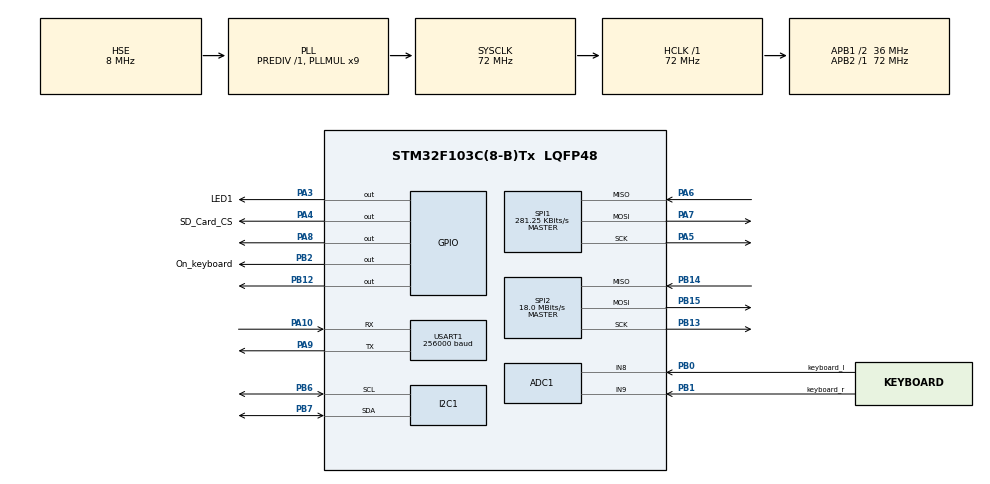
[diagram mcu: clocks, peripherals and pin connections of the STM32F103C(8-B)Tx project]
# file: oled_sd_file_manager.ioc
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ADC1.Channel-10\#ChannelRegularConversion=ADC_CHANNEL_8
ADC1.Channel-11\#ChannelRegularConversion=ADC_CHANNEL_9
ADC1.Channel-9\#ChannelRegularConversion=ADC_CHANNEL_8
ADC1.ContinuousConvMode=DISABLE
ADC1.DataAlign=ADC_DATAALIGN_RIGHT
ADC1.DiscontinuousConvMode=DISABLE
ADC1.EnableAnalogWatchDog=false
ADC1.EnableRegularConversion=ENABLE
ADC1.ExternalTrigConvEdgeChoice=NONE
ADC1.InjNumberOfConversion=0
ADC1.NbrOfConversion=2
ADC1.NbrOfConversionFlag=1
ADC1.Rank-10\#ChannelRegularConversion=2
ADC1.Rank-11\#ChannelRegularConversion=2
ADC1.Rank-9\#ChannelRegularConversion=1
ADC1.SamplingTime-10\#ChannelRegularConversion=ADC_SAMPLETIME_1CYCLE_5
ADC1.SamplingTime-11\#ChannelRegularConversion=ADC_SAMPLETIME_1CYCLE_5
ADC1.SamplingTime-9\#ChannelRegularConversion=ADC_SAMPLETIME_1CYCLE_5
ADC1.ScanConvMode=ADC_SCAN_ENABLE
ADC1.master=1
Dma.ADC1.0.Direction=DMA_PERIPH_TO_MEMORY
Dma.ADC1.0.Instance=DMA1_Channel1
Dma.ADC1.0.MemDataAlignment=DMA_MDATAALIGN_HALFWORD
Dma.ADC1.0.MemInc=DMA_MINC_ENABLE
Dma.ADC1.0.Mode=DMA_NORMAL
Dma.ADC1.0.PeriphDataAlignment=DMA_PDATAALIGN_HALFWORD
Dma.ADC1.0.PeriphInc=DMA_PINC_DISABLE
Dma.ADC1.0.Priority=DMA_PRIORITY_LOW
Dma.Request0=ADC1
I2C1.I2C_Mode=I2C_Fast
Mcu.Family=STM32F1
Mcu.Name=STM32F103C(8-B)Tx
Mcu.Package=LQFP48
NVIC.DMA1_Channel1_IRQn=true\:0\:0\:false
NVIC.PriorityGroup=NVIC_PRIORITYGROUP_4
NVIC.USART1_IRQn=true\:0\:0\:false
PA10.Mode=Asynchronous
PA10.Signal=USART1_RX
PA3.GPIO_Label=LED1
PA3.Signal=GPIO_Output
PA4.GPIO_Label=SD_Card_CS
PA4.Signal=GPIO_Output
PA5.Mode=Full_Duplex_Master
PA5.Signal=SPI1_SCK
PA6.Mode=Full_Duplex_Master
PA6.Signal=SPI1_MISO
PA7.Mode=Full_Duplex_Master
PA7.Signal=SPI1_MOSI
PA8.Signal=GPIO_Output
PA9.Mode=Asynchronous
PA9.Signal=USART1_TX
PB0.GPIO_Label=keyboard_l
PB0.Signal=ADCx_IN8
PB1.GPIO_Label=keyboard_r
PB1.Signal=ADCx_IN9
PB12.Signal=GPIO_Output
PB13.Mode=Full_Duplex_Master
PB13.Signal=SPI2_SCK
PB14.Mode=Full_Duplex_Master
PB14.Signal=SPI2_MISO
PB15.Mode=Full_Duplex_Master
PB15.Signal=SPI2_MOSI
PB2.GPIO_Label=On_keyboard
PB2.Signal=GPIO_Output
PB6.Mode=I2C
PB6.Signal=I2C1_SCL
PB7.Mode=I2C
PB7.Signal=I2C1_SDA
PD0-OSC_IN.Mode=HSE-External-Oscillator
PD0-OSC_IN.Signal=RCC_OSC_IN
PD1-OSC_OUT.Mode=HSE-External-Oscillator
PD1-OSC_OUT.Signal=RCC_OSC_OUT
ProjectManager.HeapSize=0x2710
ProjectManager.StackSize=0x200
ProjectManager.TargetToolchain=MDK-ARM V5
RCC.ADCPresc=RCC_ADCPCLK2_DIV6
RCC.AHBFreq_Value=72000000
RCC.APB1CLKDivider=RCC_HCLK_DIV2
RCC.APB1Freq_Value=36000000
RCC.APB1TimFreq_Value=72000000
RCC.APB2Freq_Value=72000000
RCC.APB2TimFreq_Value=72000000
RCC.HCLKFreq_Value=72000000
RCC.HSIState=RCC_HSI_ON
RCC.PLLMUL=RCC_PLL_MUL9
RCC.PLLSourceVirtual=RCC_PLLSOURCE_HSE
RCC.SYSCLKFreq_VALUE=72000000
RCC.SYSCLKSource=RCC_SYSCLKSOURCE_PLLCLK
RCC.USBFreq_Value=72000000
SH.ADCx_IN8.0=ADC1_IN8,IN8
SH.ADCx_IN9.0=ADC1_IN9,IN9
SPI1.BaudRatePrescaler=SPI_BAUDRATEPRESCALER_256
SPI1.CalculateBaudRate=281.25 KBits/s
SPI1.Mode=SPI_MODE_MASTER
SPI2.CalculateBaudRate=18.0 MBits/s
SPI2.Mode=SPI_MODE_MASTER
USART1.BaudRate=256000
board=oled_sd_file_manager

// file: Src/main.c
/**
  ******************************************************************************
  * File Name          : main.c
  * Description        : Main program body
  ******************************************************************************
  *
  * COPYRIGHT(c) 2016 STMicroelectronics
  *
  * Redistribution and use in source and binary forms, with or without modification,
  * are permitted provided that the following conditions are met:
  *   1. Redistributions of source code must retain the above copyright notice,
  *      this list of conditions and the following disclaimer.
  *   2. Redistributions in binary form must reproduce the above copyright notice,
  *      this list of conditions and the following disclaimer in the documentation
  *      and/or other materials provided with the distribution.
  *   3. Neither the name of STMicroelectronics nor the names of its contributors
  *      may be used to endorse or promote products derived from this software
  *      without specific prior written permission.
  *
  * THIS SOFTWARE IS PROVIDED BY THE COPYRIGHT HOLDERS AND CONTRIBUTORS "AS IS"
  * AND ANY EXPRESS OR IMPLIED WARRANTIES, INCLUDING, BUT NOT LIMITED TO, THE
  * IMPLIED WARRANTIES OF MERCHANTABILITY AND FITNESS FOR A PARTICULAR PURPOSE ARE
  * DISCLAIMED. IN NO EVENT SHALL THE COPYRIGHT HOLDER OR CONTRIBUTORS BE LIABLE
  * FOR ANY DIRECT, INDIRECT, INCIDENTAL, SPECIAL, EXEMPLARY, OR CONSEQUENTIAL
  * DAMAGES (INCLUDING, BUT NOT LIMITED TO, PROCUREMENT OF SUBSTITUTE GOODS OR
  * SERVICES; LOSS OF USE, DATA, OR PROFITS; OR BUSINESS INTERRUPTION) HOWEVER
  * CAUSED AND ON ANY THEORY OF LIABILITY, WHETHER IN CONTRACT, STRICT LIABILITY,
  * OR TORT (INCLUDING NEGLIGENCE OR OTHERWISE) ARISING IN ANY WAY OUT OF THE USE
  * OF THIS SOFTWARE, EVEN IF ADVISED OF THE POSSIBILITY OF SUCH DAMAGE.
  *
  ******************************************************************************
  */
#include "stm32f1xx_hal.h"
#include "adc.h"
#include "dma.h"
#include "i2c.h"
#include "spi.h"
#include "usart.h"
#include "gpio.h"

/* USER CODE BEGIN Includes */
#include "keyboard.h"
#include "gui.h"
#include "fm.h"
/* USER CODE END Includes */

/* USER CODE BEGIN PV */
/* Private variables ---------------------------------------------------------*/

/* USER CODE END PV */

void SystemClock_Config(void);

/* USER CODE BEGIN PFP */
/* Private function prototypes -----------------------------------------------*/

/* USER CODE END PFP */

int main(void)
{

  /* MCU Configuration----------------------------------------------------------*/

  /* Reset of all peripherals, Initializes the Flash interface and the Systick. */
  HAL_Init();

  /* Configure the system clock */
  SystemClock_Config();

  /* Initialize all configured peripherals */
  MX_GPIO_Init();
  MX_DMA_Init();
  MX_ADC1_Init();
  MX_I2C1_Init();
  MX_SPI1_Init();
  MX_SPI2_Init();
  MX_USART1_UART_Init();

  /* USER CODE BEGIN 2 */
	printf("Start\n");
	keyboard_init();
	gui_init();

	keyboard_setPressHandler(&gui_input);

	fm_init();

	gui_set_cur_app(fm_draw, fm_input);

  /* USER CODE END 2 */

  /* Infinite loop */
  while (1)
  {
		keyboard_update();

		gui_draw();
  }

}

/** System Clock Configuration
*/
void SystemClock_Config(void)
{

  RCC_OscInitTypeDef RCC_OscInitStruct;
  RCC_ClkInitTypeDef RCC_ClkInitStruct;
  RCC_PeriphCLKInitTypeDef PeriphClkInit;

  RCC_OscInitStruct.OscillatorType = RCC_OSCILLATORTYPE_HSE;
  RCC_OscInitStruct.HSEState = RCC_HSE_ON;
  RCC_OscInitStruct.HSEPredivValue = RCC_HSE_PREDIV_DIV1;
  RCC_OscInitStruct.PLL.PLLState = RCC_PLL_ON;
  RCC_OscInitStruct.PLL.PLLSource = RCC_PLLSOURCE_HSE;
  RCC_OscInitStruct.PLL.PLLMUL = RCC_PLL_MUL9;
  HAL_RCC_OscConfig(&RCC_OscInitStruct);

  RCC_ClkInitStruct.ClockType = RCC_CLOCKTYPE_HCLK|RCC_CLOCKTYPE_SYSCLK
                              |RCC_CLOCKTYPE_PCLK1|RCC_CLOCKTYPE_PCLK2;
  RCC_ClkInitStruct.SYSCLKSource = RCC_SYSCLKSOURCE_PLLCLK;
  RCC_ClkInitStruct.AHBCLKDivider = RCC_SYSCLK_DIV1;
  RCC_ClkInitStruct.APB1CLKDivider = RCC_HCLK_DIV2;
  RCC_ClkInitStruct.APB2CLKDivider = RCC_HCLK_DIV1;
  HAL_RCC_ClockConfig(&RCC_ClkInitStruct, FLASH_LATENCY_2);

  PeriphClkInit.PeriphClockSelection = RCC_PERIPHCLK_ADC;
  PeriphClkInit.AdcClockSelection = RCC_ADCPCLK2_DIV6;
  HAL_RCCEx_PeriphCLKConfig(&PeriphClkInit);

  HAL_SYSTICK_Config(HAL_RCC_GetHCLKFreq()/1000);

  HAL_SYSTICK_CLKSourceConfig(SYSTICK_CLKSOURCE_HCLK);

  /* SysTick_IRQn interrupt configuration */
  HAL_NVIC_SetPriority(SysTick_IRQn, 0, 0);
}

/************************ (C) COPYRIGHT STMicroelectronics *****END OF FILE****/
